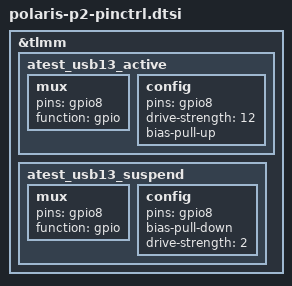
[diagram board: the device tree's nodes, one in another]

/* Copyright (c) 2016-2017, The Linux Foundation. All rights reserved.
 * Copyright (C) 2018 XiaoMi, Inc.
 *
 * This program is free software; you can redistribute it and/or modify
 * it under the terms of the GNU General Public License version 2 and
 * only version 2 as published by the Free Software Foundation.
 *
 * This program is distributed in the hope that it will be useful,
 * but WITHOUT ANY WARRANTY; without even the implied warranty of
 * MERCHANTABILITY or FITNESS FOR A PARTICULAR PURPOSE.  See the
 * GNU General Public License for more details.
 */
#include "polaris-p1-pinctrl.dtsi"

&tlmm {
	atest_usb13_active: atest_usb13_active {
		mux {
			pins = "gpio8";
			function = "gpio";
		};
		config {
			pins = "gpio8";
			drive-strength = <12>;
			bias-pull-up;
		};
	};

	atest_usb13_suspend: atest_usb13_suspend {
		mux {
			pins = "gpio8";
			function = "gpio";
		};
		config {
			pins = "gpio8";
			bias-pull-down;
			drive-strength = <2>;
		};
	};
};

